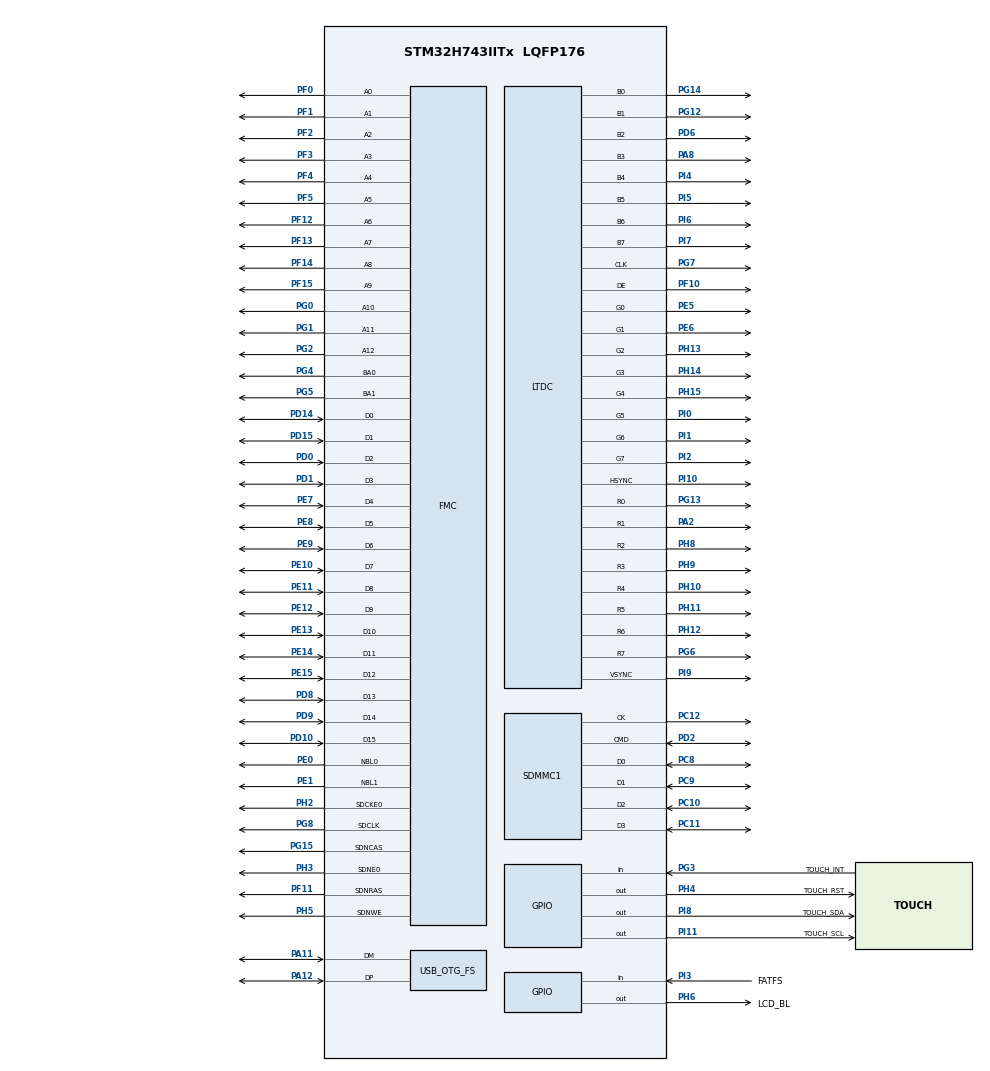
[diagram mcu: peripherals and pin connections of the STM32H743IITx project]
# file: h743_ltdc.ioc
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CORTEX_M7.AccessPermission-Cortex_Memory_Protection_Unit_Region0_Settings=MPU_REGION_FULL_ACCESS
CORTEX_M7.AccessPermission-Cortex_Memory_Protection_Unit_Region1_Settings=MPU_REGION_FULL_ACCESS
CORTEX_M7.AccessPermission-Cortex_Memory_Protection_Unit_Region2_Settings=MPU_REGION_FULL_ACCESS
CORTEX_M7.AccessPermission-Cortex_Memory_Protection_Unit_Region3_Settings=MPU_REGION_FULL_ACCESS
CORTEX_M7.AccessPermission-Cortex_Memory_Protection_Unit_Region4_Settings=MPU_REGION_FULL_ACCESS
CORTEX_M7.BaseAddress-Cortex_Memory_Protection_Unit_Region0_Settings=0x24000000
CORTEX_M7.BaseAddress-Cortex_Memory_Protection_Unit_Region1_Settings=0x30000000
CORTEX_M7.BaseAddress-Cortex_Memory_Protection_Unit_Region2_Settings=0x38000000
CORTEX_M7.BaseAddress-Cortex_Memory_Protection_Unit_Region3_Settings=0xC0000000
CORTEX_M7.BaseAddress-Cortex_Memory_Protection_Unit_Region4_Settings=0x90000000
CORTEX_M7.CPU_DCache=Enabled
CORTEX_M7.CPU_ICache=Enabled
CORTEX_M7.Enable-Cortex_Memory_Protection_Unit_Region0_Settings=MPU_REGION_ENABLE
CORTEX_M7.Enable-Cortex_Memory_Protection_Unit_Region1_Settings=MPU_REGION_ENABLE
CORTEX_M7.Enable-Cortex_Memory_Protection_Unit_Region2_Settings=MPU_REGION_ENABLE
CORTEX_M7.Enable-Cortex_Memory_Protection_Unit_Region3_Settings=MPU_REGION_ENABLE
CORTEX_M7.Enable-Cortex_Memory_Protection_Unit_Region4_Settings=MPU_REGION_ENABLE
CORTEX_M7.IsBufferable-Cortex_Memory_Protection_Unit_Region0_Settings=MPU_ACCESS_BUFFERABLE
CORTEX_M7.IsBufferable-Cortex_Memory_Protection_Unit_Region1_Settings=MPU_ACCESS_BUFFERABLE
CORTEX_M7.IsBufferable-Cortex_Memory_Protection_Unit_Region2_Settings=MPU_ACCESS_BUFFERABLE
CORTEX_M7.IsBufferable-Cortex_Memory_Protection_Unit_Region3_Settings=MPU_ACCESS_BUFFERABLE
CORTEX_M7.IsBufferable-Cortex_Memory_Protection_Unit_Region4_Settings=MPU_ACCESS_BUFFERABLE
CORTEX_M7.IsCacheable-Cortex_Memory_Protection_Unit_Region0_Settings=MPU_ACCESS_CACHEABLE
CORTEX_M7.IsCacheable-Cortex_Memory_Protection_Unit_Region1_Settings=MPU_ACCESS_CACHEABLE
CORTEX_M7.IsCacheable-Cortex_Memory_Protection_Unit_Region2_Settings=MPU_ACCESS_CACHEABLE
CORTEX_M7.IsCacheable-Cortex_Memory_Protection_Unit_Region3_Settings=MPU_ACCESS_CACHEABLE
CORTEX_M7.IsCacheable-Cortex_Memory_Protection_Unit_Region4_Settings=MPU_ACCESS_CACHEABLE
CORTEX_M7.MPU_Control=MPU_PRIVILEGED_DEFAULT
CORTEX_M7.Size-Cortex_Memory_Protection_Unit_Region0_Settings=MPU_REGION_SIZE_512KB
CORTEX_M7.Size-Cortex_Memory_Protection_Unit_Region1_Settings=MPU_REGION_SIZE_512KB
CORTEX_M7.Size-Cortex_Memory_Protection_Unit_Region2_Settings=MPU_REGION_SIZE_64KB
CORTEX_M7.Size-Cortex_Memory_Protection_Unit_Region3_Settings=MPU_REGION_SIZE_32MB
CORTEX_M7.Size-Cortex_Memory_Protection_Unit_Region4_Settings=MPU_REGION_SIZE_8MB
CORTEX_M7.TypeExtField-Cortex_Memory_Protection_Unit_Region0_Settings=MPU_TEX_LEVEL1
CORTEX_M7.TypeExtField-Cortex_Memory_Protection_Unit_Region1_Settings=MPU_TEX_LEVEL1
CORTEX_M7.TypeExtField-Cortex_Memory_Protection_Unit_Region2_Settings=MPU_TEX_LEVEL1
CORTEX_M7.TypeExtField-Cortex_Memory_Protection_Unit_Region3_Settings=MPU_TEX_LEVEL1
CORTEX_M7.TypeExtField-Cortex_Memory_Protection_Unit_Region4_Settings=MPU_TEX_LEVEL1
DMA2D.ColorMode=DMA2D_OUTPUT_RGB888
DMA2D.Mode=DMA2D_R2M
Dma.MEMTOMEM.0.Direction=DMA_MEMORY_TO_MEMORY
Dma.MEMTOMEM.0.EventEnable=DISABLE
Dma.MEMTOMEM.0.FIFOMode=DMA_FIFOMODE_ENABLE
Dma.MEMTOMEM.0.FIFOThreshold=DMA_FIFO_THRESHOLD_FULL
Dma.MEMTOMEM.0.Instance=DMA1_Stream0
Dma.MEMTOMEM.0.MemBurst=DMA_MBURST_SINGLE
Dma.MEMTOMEM.0.MemDataAlignment=DMA_MDATAALIGN_HALFWORD
Dma.MEMTOMEM.0.MemInc=DMA_MINC_ENABLE
Dma.MEMTOMEM.0.Mode=DMA_NORMAL
Dma.MEMTOMEM.0.PeriphBurst=DMA_PBURST_SINGLE
Dma.MEMTOMEM.0.PeriphDataAlignment=DMA_PDATAALIGN_HALFWORD
Dma.MEMTOMEM.0.PeriphInc=DMA_PINC_ENABLE
Dma.MEMTOMEM.0.Polarity=HAL_DMAMUX_REQ_GEN_RISING
Dma.MEMTOMEM.0.Priority=DMA_PRIORITY_LOW
Dma.MEMTOMEM.0.RequestNumber=1
Dma.MEMTOMEM.0.SignalID=NONE
Dma.MEMTOMEM.0.SyncEnable=DISABLE
Dma.MEMTOMEM.0.SyncPolarity=HAL_DMAMUX_SYNC_NO_EVENT
Dma.MEMTOMEM.0.SyncRequestNumber=1
Dma.MEMTOMEM.0.SyncSignalID=NONE
Dma.Request0=MEMTOMEM
FATFS.BSP.number=1
FATFS0.BSP.STBoard=false
FATFS0.BSP.api=Unknown
FATFS0.BSP.i2caddr=0
FATFS0.BSP.instance=PI3
FATFS0.BSP.ip=GPIO
FATFS0.BSP.mode=Input
FATFS0.BSP.name=Detect_SDIO
FATFS0.BSP.solution=PI3
FMC.CASLatency1=FMC_SDRAM_CAS_LATENCY_3
FMC.ColumnBitsNumber1=FMC_SDRAM_COLUMN_BITS_NUM_9
FMC.ExitSelfRefreshDelay1=7
FMC.LoadToActiveDelay1=2
FMC.RCDDelay1=2
FMC.RPDelay1=2
FMC.ReadBurst1=FMC_SDRAM_RBURST_ENABLE
FMC.ReadPipeDelay1=FMC_SDRAM_RPIPE_DELAY_1
FMC.RowCycleDelay1=7
FMC.SDClockPeriod1=FMC_SDRAM_CLOCK_PERIOD_2
FMC.SelfRefreshTime1=4
FMC.WriteRecoveryTime1=3
JPEG.JPEG_RGB_FORMAT=JPEG_RGB888
LTDC.ActiveW=800
LTDC.Alpha0_L0=0
LTDC.Alpha_L0=255
LTDC.BlendingFactor1_L0=LTDC_BLENDING_FACTOR1_CA
LTDC.BlendingFactor2_L0=LTDC_BLENDING_FACTOR2_CA
LTDC.Blue=0
LTDC.DEPolarity=LTDC_DEPOLARITY_AL
LTDC.FBStartAdress_L0=0xC0000000
LTDC.Green=0
LTDC.HBP=88
LTDC.HFP=40
LTDC.HSync=48
LTDC.ImageHeight_L0=480
LTDC.ImageWidth_L0=800
LTDC.Layers=0
LTDC.PixelFormat_L0=LTDC_PIXEL_FORMAT_RGB888
LTDC.Red=0
LTDC.VBP=32
LTDC.VFP=13
LTDC.VSync=3
LTDC.WindowX1_L0=800
LTDC.WindowX1_L1=479
LTDC.WindowY1_L0=480
LTDC.WindowY1_L1=799
Mcu.Family=STM32H7
Mcu.Name=STM32H743IITx
Mcu.Package=LQFP176
NVIC.DMA2D_IRQn=true\:0\:0\:false\:false\:true\:true\:true
NVIC.FMC_IRQn=true\:0\:0\:false\:false\:true\:true\:true
NVIC.JPEG_IRQn=true\:0\:0\:false\:false\:true\:true\:true
NVIC.LTDC_IRQn=true\:0\:0\:false\:false\:true\:true\:true
NVIC.OTG_FS_IRQn=true\:0\:0\:false\:false\:true\:false\:true
NVIC.PriorityGroup=NVIC_PRIORITYGROUP_4
NVIC.SDMMC1_IRQn=true\:0\:0\:false\:false\:true\:true\:true
NVIC.TIM2_IRQn=true\:0\:0\:false\:false\:true\:true\:true
NVIC.TIM3_IRQn=true\:0\:0\:false\:false\:true\:true\:true
NVIC.TIM4_IRQn=true\:0\:0\:false\:false\:true\:true\:true
NVIC.TIM5_IRQn=true\:0\:0\:false\:false\:true\:true\:true
PA11.GPIO_Speed=GPIO_SPEED_FREQ_HIGH
PA11.Mode=Device_Only
PA11.Signal=USB_OTG_FS_DM
PA12.GPIO_Speed=GPIO_SPEED_FREQ_HIGH
PA12.Mode=Device_Only
PA12.Signal=USB_OTG_FS_DP
PA13\ (JTMS/SWDIO).Mode=Serial_Wire
PA13\ (JTMS/SWDIO).Signal=DEBUG_JTMS-SWDIO
PA14\ (JTCK/SWCLK).Mode=Serial_Wire
PA14\ (JTCK/SWCLK).Signal=DEBUG_JTCK-SWCLK
PA2.GPIO_Speed=GPIO_SPEED_FREQ_VERY_HIGH
PA2.Mode=RGB888
PA2.Signal=LTDC_R1
PA8.GPIO_Speed=GPIO_SPEED_FREQ_VERY_HIGH
PA8.Mode=RGB888
PA8.Signal=LTDC_B3
PC10.Mode=SD_4_bits_Wide_bus
PC10.Signal=SDMMC1_D2
PC11.Mode=SD_4_bits_Wide_bus
PC11.Signal=SDMMC1_D3
PC12.Mode=SD_4_bits_Wide_bus
PC12.Signal=SDMMC1_CK
PC14-OSC32_IN\ (OSC32_IN).Mode=LSE-External-Oscillator
PC14-OSC32_IN\ (OSC32_IN).Signal=RCC_OSC32_IN
PC15-OSC32_OUT\ (OSC32_OUT).Mode=LSE-External-Oscillator
PC15-OSC32_OUT\ (OSC32_OUT).Signal=RCC_OSC32_OUT
PC8.Mode=SD_4_bits_Wide_bus
PC8.Signal=SDMMC1_D0
PC9.Mode=SD_4_bits_Wide_bus
PC9.Signal=SDMMC1_D1
PD0.Signal=FMC_D2_DA2
PD1.Signal=FMC_D3_DA3
PD10.Signal=FMC_D15_DA15
PD14.Signal=FMC_D0_DA0
PD15.Signal=FMC_D1_DA1
PD2.Mode=SD_4_bits_Wide_bus
PD2.Signal=SDMMC1_CMD
PD6.GPIO_Speed=GPIO_SPEED_FREQ_VERY_HIGH
PD6.Mode=RGB888
PD6.Signal=LTDC_B2
PD8.Signal=FMC_D13_DA13
PD9.Signal=FMC_D14_DA14
PE0.Signal=FMC_NBL0
PE1.Signal=FMC_NBL1
PE10.Signal=FMC_D7_DA7
PE11.Signal=FMC_D8_DA8
PE12.Signal=FMC_D9_DA9
PE13.Signal=FMC_D10_DA10
PE14.Signal=FMC_D11_DA11
PE15.Signal=FMC_D12_DA12
PE5.GPIO_Speed=GPIO_SPEED_FREQ_VERY_HIGH
PE5.Mode=RGB888
PE5.Signal=LTDC_G0
PE6.GPIO_Speed=GPIO_SPEED_FREQ_VERY_HIGH
PE6.Mode=RGB888
PE6.Signal=LTDC_G1
PE7.Signal=FMC_D4_DA4
PE8.Signal=FMC_D5_DA5
PE9.Signal=FMC_D6_DA6
PF0.Signal=FMC_A0
PF1.Signal=FMC_A1
PF10.GPIO_Speed=GPIO_SPEED_FREQ_VERY_HIGH
PF10.Mode=RGB888
PF10.Signal=LTDC_DE
PF11.Signal=FMC_SDNRAS
PF12.Signal=FMC_A6
PF13.Signal=FMC_A7
PF14.Signal=FMC_A8
PF15.Signal=FMC_A9
PF2.Signal=FMC_A2
PF3.Signal=FMC_A3
PF4.Signal=FMC_A4
PF5.Signal=FMC_A5
PG0.Signal=FMC_A10
PG1.Signal=FMC_A11
PG12.GPIO_Speed=GPIO_SPEED_FREQ_VERY_HIGH
PG12.Mode=RGB888
PG12.Signal=LTDC_B1
PG13.GPIO_Speed=GPIO_SPEED_FREQ_VERY_HIGH
PG13.Mode=RGB888
PG13.Signal=LTDC_R0
PG14.GPIO_Speed=GPIO_SPEED_FREQ_VERY_HIGH
PG14.Mode=RGB888
PG14.Signal=LTDC_B0
PG15.Signal=FMC_SDNCAS
PG2.Signal=FMC_A12
PG3.GPIO_Label=TOUCH_INT
PG3.Signal=GPIO_Input
PG4.Signal=FMC_A14_BA0
PG5.Signal=FMC_A15_BA1
PG6.GPIO_Speed=GPIO_SPEED_FREQ_VERY_HIGH
PG6.Mode=RGB888
PG6.Signal=LTDC_R7
PG7.GPIO_Speed=GPIO_SPEED_FREQ_VERY_HIGH
PG7.Mode=RGB888
PG7.Signal=LTDC_CLK
PG8.Signal=FMC_SDCLK
PH0-OSC_IN\ (PH0).Mode=HSE-External-Oscillator
PH0-OSC_IN\ (PH0).Signal=RCC_OSC_IN
PH1-OSC_OUT\ (PH1).Mode=HSE-External-Oscillator
PH1-OSC_OUT\ (PH1).Signal=RCC_OSC_OUT
PH10.GPIO_Speed=GPIO_SPEED_FREQ_VERY_HIGH
PH10.Mode=RGB888
PH10.Signal=LTDC_R4
PH11.GPIO_Speed=GPIO_SPEED_FREQ_VERY_HIGH
PH11.Mode=RGB888
PH11.Signal=LTDC_R5
PH12.GPIO_Speed=GPIO_SPEED_FREQ_VERY_HIGH
PH12.Mode=RGB888
PH12.Signal=LTDC_R6
PH13.GPIO_Speed=GPIO_SPEED_FREQ_VERY_HIGH
PH13.Mode=RGB888
PH13.Signal=LTDC_G2
PH14.GPIO_Speed=GPIO_SPEED_FREQ_VERY_HIGH
PH14.Mode=RGB888
PH14.Signal=LTDC_G3
PH15.GPIO_Speed=GPIO_SPEED_FREQ_VERY_HIGH
PH15.Mode=RGB888
PH15.Signal=LTDC_G4
PH2.Mode=SdramChipSelect1_1
PH2.Signal=FMC_SDCKE0
PH3.Mode=SdramChipSelect1_1
PH3.Signal=FMC_SDNE0
PH4.GPIO_Label=TOUCH_RST
PH4.GPIO_PuPd=GPIO_PULLUP
PH4.Signal=GPIO_Output
PH5.Signal=FMC_SDNWE
PH6.GPIO_Label=LCD_BL
PH6.GPIO_PuPd=GPIO_PULLUP
PH6.Signal=GPIO_Output
PH8.GPIO_Speed=GPIO_SPEED_FREQ_VERY_HIGH
PH8.Mode=RGB888
PH8.Signal=LTDC_R2
PH9.GPIO_Speed=GPIO_SPEED_FREQ_VERY_HIGH
PH9.Mode=RGB888
PH9.Signal=LTDC_R3
PI0.GPIO_Speed=GPIO_SPEED_FREQ_VERY_HIGH
PI0.Mode=RGB888
PI0.Signal=LTDC_G5
PI1.GPIO_Speed=GPIO_SPEED_FREQ_VERY_HIGH
PI1.Mode=RGB888
PI1.Signal=LTDC_G6
PI10.GPIO_Speed=GPIO_SPEED_FREQ_VERY_HIGH
PI10.Mode=RGB888
PI10.Signal=LTDC_HSYNC
PI11.GPIO_Label=TOUCH_SCL
PI11.GPIO_PuPd=GPIO_PULLUP
PI11.Signal=GPIO_Output
PI2.GPIO_Speed=GPIO_SPEED_FREQ_VERY_HIGH
PI2.Mode=RGB888
PI2.Signal=LTDC_G7
PI3.GPIO_Label=FATFS
PI3.GPIO_PuPd=GPIO_PULLDOWN
PI3.Signal=GPIO_Input
PI4.GPIO_Speed=GPIO_SPEED_FREQ_VERY_HIGH
PI4.Mode=RGB888
PI4.Signal=LTDC_B4
PI5.GPIO_Speed=GPIO_SPEED_FREQ_VERY_HIGH
PI5.Mode=RGB888
PI5.Signal=LTDC_B5
PI6.GPIO_Speed=GPIO_SPEED_FREQ_VERY_HIGH
PI6.Mode=RGB888
PI6.Signal=LTDC_B6
PI7.GPIO_Speed=GPIO_SPEED_FREQ_VERY_HIGH
PI7.Mode=RGB888
PI7.Signal=LTDC_B7
PI8.GPIO_Label=TOUCH_SDA
PI8.GPIO_PuPd=GPIO_PULLUP
PI8.Signal=GPIO_Output
PI9.GPIO_Speed=GPIO_SPEED_FREQ_VERY_HIGH
PI9.Mode=RGB888
PI9.Signal=LTDC_VSYNC
ProjectManager.HeapSize=0x2000
ProjectManager.StackSize=0x2000
ProjectManager.TargetToolchain=STM32CubeIDE
RCC.ADCFreq_Value=50390625
RCC.APB1Freq_Value=120000000
RCC.APB2Freq_Value=120000000
RCC.APB3Freq_Value=120000000
RCC.APB4Freq_Value=120000000
RCC.CortexFreq_Value=480000000
RCC.D1PPRE=RCC_APB3_DIV2
RCC.D2PPRE1=RCC_APB1_DIV2
RCC.D2PPRE2=RCC_APB2_DIV2
RCC.D3PPRE=RCC_APB4_DIV2
RCC.DIVM1=5
RCC.DIVM3=25
RCC.DIVN1=192
RCC.DIVN3=192
RCC.DIVQ1=32
RCC.DIVQ3=4
RCC.DIVR3=6
RCC.HCLKFreq_Value=240000000
RCC.HPRE=RCC_HCLK_DIV2
RCC.PLLSourceVirtual=RCC_PLLSOURCE_HSE
RCC.SYSCLKFreq_VALUE=480000000
RCC.SYSCLKSource=RCC_SYSCLKSOURCE_PLLCLK
RCC.USBCLockSelection=RCC_USBCLKSOURCE_PLL3
RCC.USBFreq_Value=48000000
SH.FMC_A0.0=FMC_A0,13b-sda1
SH.FMC_A1.0=FMC_A1,13b-sda1
SH.FMC_A10.0=FMC_A10,13b-sda1
SH.FMC_A11.0=FMC_A11,13b-sda1
SH.FMC_A12.0=FMC_A12,13b-sda1
SH.FMC_A14_BA0.0=FMC_BA0,FourSdramBanks1
SH.FMC_A15_BA1.0=FMC_BA1,FourSdramBanks1
SH.FMC_A2.0=FMC_A2,13b-sda1
SH.FMC_A3.0=FMC_A3,13b-sda1
SH.FMC_A4.0=FMC_A4,13b-sda1
SH.FMC_A5.0=FMC_A5,13b-sda1
SH.FMC_A6.0=FMC_A6,13b-sda1
SH.FMC_A7.0=FMC_A7,13b-sda1
SH.FMC_A8.0=FMC_A8,13b-sda1
SH.FMC_A9.0=FMC_A9,13b-sda1
SH.FMC_D0_DA0.0=FMC_D0,sd-16b-d1
SH.FMC_D10_DA10.0=FMC_D10,sd-16b-d1
SH.FMC_D11_DA11.0=FMC_D11,sd-16b-d1
SH.FMC_D12_DA12.0=FMC_D12,sd-16b-d1
SH.FMC_D13_DA13.0=FMC_D13,sd-16b-d1
SH.FMC_D14_DA14.0=FMC_D14,sd-16b-d1
SH.FMC_D15_DA15.0=FMC_D15,sd-16b-d1
SH.FMC_D1_DA1.0=FMC_D1,sd-16b-d1
SH.FMC_D2_DA2.0=FMC_D2,sd-16b-d1
SH.FMC_D3_DA3.0=FMC_D3,sd-16b-d1
SH.FMC_D4_DA4.0=FMC_D4,sd-16b-d1
SH.FMC_D5_DA5.0=FMC_D5,sd-16b-d1
SH.FMC_D6_DA6.0=FMC_D6,sd-16b-d1
SH.FMC_D7_DA7.0=FMC_D7,sd-16b-d1
SH.FMC_D8_DA8.0=FMC_D8,sd-16b-d1
SH.FMC_D9_DA9.0=FMC_D9,sd-16b-d1
SH.FMC_NBL0.0=FMC_NBL0,Sd2ByteEnable1
SH.FMC_NBL1.0=FMC_NBL1,Sd2ByteEnable1
SH.FMC_SDCLK.0=FMC_SDCLK,13b-sda1
SH.FMC_SDNCAS.0=FMC_SDNCAS,13b-sda1
SH.FMC_SDNRAS.0=FMC_SDNRAS,13b-sda1
SH.FMC_SDNWE.0=FMC_SDNWE,13b-sda1
USB_DEVICE.CLASS_NAME_FS=CDC
USB_DEVICE.VirtualMode-CDC_FS=Cdc
USB_DEVICE.VirtualModeFS=Cdc_FS
USB_OTG_FS.VirtualMode=Device_Only
VP_DMA2D_VS_DMA2D.Mode=DMA2D_Activate
VP_FATFS_VS_SDIO.Mode=SDIO
VP_JPEG_VS_JPEG.Mode=JPEG_Activate
VP_TIM2_VS_ClockSourceINT.Mode=Internal
VP_TIM3_VS_ClockSourceINT.Mode=Internal
VP_TIM4_VS_ClockSourceINT.Mode=Internal
VP_TIM5_VS_ClockSourceINT.Mode=Internal
VP_USB_DEVICE_VS_USB_DEVICE_CDC_FS.Mode=CDC_FS
board=custom

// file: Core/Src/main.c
/* USER CODE BEGIN Header */
/**
  ******************************************************************************
  * @file           : main.c
  * @brief          : Main program body
  ******************************************************************************
  * @attention
  *
  * Copyright (c) 2023 STMicroelectronics.
  * All rights reserved.
  *
  * This software is licensed under terms that can be found in the LICENSE file
  * in the root directory of this software component.
  * If no LICENSE file comes with this software, it is provided AS-IS.
  *
  ******************************************************************************
  */
/* USER CODE END Header */
#include "main.h"
#include "dma.h"
#include "dma2d.h"
#include "fatfs.h"
#include "jpeg.h"
#include "ltdc.h"
#include "sdmmc.h"
#include "tim.h"
#include "usb_device.h"
#include "gpio.h"
#include "fmc.h"

/* USER CODE BEGIN Includes */
#include <stdio.h>
#include <string.h>
#include <stdlib.h>
#include "usbd_cdc_if.h"
#include "pic.h"

extern unsigned char gImage_pic[];
/* USER CODE END Includes */

/* USER CODE BEGIN PD */
#define one_clk_time	0.00416666f
#define SDRAM_Size 		32*1024*1024
#define SDRAM_BASEADDRESS	0xC0000000
#define DTCM_BASEADDRESS	0x20000000

#define LCD_ON	HAL_GPIO_WritePin(GPIOH, GPIO_PIN_6, GPIO_PIN_SET)
#define LCD_OFF	HAL_GPIO_WritePin(GPIOH, GPIO_PIN_6, GPIO_PIN_RESET)

/* USER CODE END PD */

void SystemClock_Config(void);
void PeriphCommonClock_Config(void);
static void MPU_Config(void);

/* USER CODE BEGIN 0 */
#define	p_buf

#ifdef	p_buf
	uint16_t *buf = (uint16_t *)0xC0000000;
#else
	SDRAM uint16_t buf[SDRAM_Size/2] = {0};
#endif
uint32_t	tim_start,tim_end;
uint32_t	tim_long;
float		time_us;
uint32_t Get_TIM_CNT(TIM_HandleTypeDef htim)
{
	return	htim.Instance->CNT;
}

uint8_t SDRAM_Test(void)
{
	volatile uint32_t  i = 0;			// ¼ÆÊý±äÁ¿
	uint32_t k = 0;
	uint16_t ReadData = 0; 	// ¶ÁÈ¡µ½µÄÊý¾Ý
	uint32_t Err_Num = 0;

	float    ExecutionSpeed;			// Ö´ÐÐËÙ¶È
	htim2.Instance->CNT = 0;
	tim_start = Get_TIM_CNT(htim2);
	HAL_TIM_Base_Start(&htim2);
	HAL_Delay(100);
	tim_end = Get_TIM_CNT(htim2);
	HAL_TIM_Base_Stop(&htim2);
	tim_long = tim_end - tim_start;
	time_us = tim_long * one_clk_time;
	usb_printf("\r\n delay %.2f us!\r\n", time_us);
	HAL_Delay(10);

	usb_printf("\r\n SDRAM Write an Read test start!\r\n");
	HAL_Delay(10);

	htim2.Instance->CNT = 0;
	tim_start = Get_TIM_CNT(htim2);
	HAL_TIM_Base_Start(&htim2);
	for (k = 0; k < SDRAM_Size/2; k++)
	{
		buf[k] = (uint16_t)k;
	}
	tim_end = Get_TIM_CNT(htim2);
	HAL_TIM_Base_Stop(&htim2);
	tim_long = tim_end - tim_start;
	time_us = tim_long * one_clk_time;
	ExecutionSpeed = (float)SDRAM_Size /1024/1024 /time_us*1000*1000 ;

	usb_printf("\r\nWrite Speed is %.2f MB/s\r\n",ExecutionSpeed);
	HAL_Delay(10);

	htim2.Instance->CNT = 0;
	tim_start = Get_TIM_CNT(htim2);
	HAL_TIM_Base_Start(&htim2);
	for(i = 0; i < SDRAM_Size/2;i++ )
	{
		ReadData = buf[i];  // ´ÓSDRAM¶Á³öÊý¾Ý
	}
	tim_end = Get_TIM_CNT(htim2);
	HAL_TIM_Base_Stop(&htim2);
	tim_long = tim_end - tim_start;
	time_us = tim_long * one_clk_time;

	ExecutionSpeed = (float)SDRAM_Size /1024/1024 /time_us*1000*1000 ;

	usb_printf("\r\nRead Speed is %.2f MB/s\r\n",ExecutionSpeed);
	HAL_Delay(10);

	usb_printf("\r\nstart 16bits test\r\n");
	HAL_Delay(10);
	for(i = 0; i < SDRAM_Size/2;i++ )
	{
		ReadData = buf[i];
		if( ReadData != (uint16_t)i )
		{
			Err_Num++;
		}
	}
	if(Err_Num != 0){
		usb_printf("\r\nSDRAM test failed , %d\r\n", Err_Num);
		HAL_Delay(10);
		return ERROR;
	}

	usb_printf("SDRAM OK\r\n");
	return SUCCESS;
}

uint8_t *frame_buf = (uint8_t *)(SDRAM_BASEADDRESS);
uint8_t *frame = (uint8_t *)(SDRAM_BASEADDRESS + 800*480*3);

void DMA2D_FillColor(uint16_t sx, uint16_t sy, uint16_t ex, uint16_t ey, uint32_t color)
{

	uint32_t addr = (uint32_t)frame_buf + 3*(800*sy + sx);
	uint32_t offline = 800 - (ex - sx + 1);

	__HAL_RCC_DMA2D_CLK_ENABLE();
	DMA2D->CR &= ~DMA2D_CR_START;
	DMA2D->CR = DMA2D_R2M;
	DMA2D->OPFCCR = LTDC_PIXEL_FORMAT_RGB888;
	DMA2D->OMAR = addr;

	DMA2D->OOR = offline;
	DMA2D->NLR = ((ex - sx + 1) << 16) | ((ey - sy + 1) << 0);
	DMA2D->OCOLR = color;

	DMA2D->CR |= DMA2D_CR_START;

	while((DMA2D->ISR & DMA2D_FLAG_TC) == 0)
	{

	}
	DMA2D->IFCR |= DMA2D_FLAG_TC;
}

void DMA2D_FillFrame(uint16_t sx, uint16_t sy, uint16_t ex, uint16_t ey, uint32_t *color)
{

	uint32_t addr = (uint32_t)frame_buf + 3*(800*sy + sx);
	uint32_t offline = 800 - (ex - sx + 1);
	uint32_t size = (ex - sx + 1)*(ey - sy + 1)*3;

	__HAL_RCC_DMA2D_CLK_ENABLE();
	DMA2D->CR &= ~DMA2D_CR_START;
	DMA2D->CR = DMA2D_M2M;
	DMA2D->FGPFCCR = LTDC_PIXEL_FORMAT_RGB888;

	DMA2D->FGMAR = (uint32_t)color;
	DMA2D->OMAR = addr;

	DMA2D->FGOR = 0;
	DMA2D->OOR = offline;
	DMA2D->NLR = ((ex - sx + 1) << 16) | ((ey - sy + 1) << 0);

	SCB_CleanDCache_by_Addr((uint32_t *)color, size);
//	SCB_CleanDCache();

	DMA2D->CR |= DMA2D_CR_START;

	while((DMA2D->ISR & DMA2D_FLAG_TC) == 0)
	{

	}
	DMA2D->IFCR |= DMA2D_FLAG_TC;
}

uint32_t color = 0xff;
uint32_t cnt = 0;

/* USER CODE END 0 */

int main(void)
{

  /* MPU Configuration--------------------------------------------------------*/
  MPU_Config();

  /* Enable I-Cache---------------------------------------------------------*/
  SCB_EnableICache();

  /* Enable D-Cache---------------------------------------------------------*/
  SCB_EnableDCache();//刷屏后记得FlushDCache，不然会有画面问题

  /* MCU Configuration--------------------------------------------------------*/

  /* Reset of all peripherals, Initializes the Flash interface and the Systick. */
  HAL_Init();

  /* Configure the system clock */
  SystemClock_Config();

/* Configure the peripherals common clocks */
  PeriphCommonClock_Config();

  /* Initialize all configured peripherals */
  MX_GPIO_Init();
  MX_DMA2D_Init();
  MX_FMC_Init();
  MX_JPEG_Init();
  MX_LTDC_Init();
  MX_SDMMC1_SD_Init();
  MX_TIM2_Init();
  MX_TIM3_Init();
  MX_TIM4_Init();
  MX_TIM5_Init();
  MX_FATFS_Init();
  MX_DMA_Init();
  MX_USB_DEVICE_Init();
  /* USER CODE BEGIN 2 */
  LCD_ON;

//  for(int i=0; i<480*800*3; i++)
//  {
//	  if(i%3==0)
//		  frame_buf[i] = 0xff;
//	  else if(i%3==1)
//		  frame_buf[i] = 0xff;
//	  else if(i%3==2)
//		  frame_buf[i] = 0xff;
//  }
  DMA2D_FillColor(0, 0, 799, 479, 0x00);

  uint32_t *p = (uint32_t *)0x20000000;
  *p = 0xffffffff;
  /* USER CODE END 2 */

  /* Infinite loop */
  while (1)
  {

    /* USER CODE BEGIN 3 */

	  //SDRAM_Test();
//	  for(int i=0; i<480*800*3; i++)
//	  {
//		  if(i%3==0)
//			  frame[i] = color;
//		  else if(i%3==1)
//			  frame[i] = color>>8;
//		  else if(i%3==2)
//			  frame[i] = color>>16;
//	  }
	  //SCB_CleanDCache_by_Addr((uint32_t *)frame, 3*800*480);
//	  color++;
//	  DMA2D_FillFrame(0, 0, 799, 479, (uint32_t *)frame);
//	  DMA2D_FillFrame(0, 0, 773, 479, (uint32_t *)gImage_pic);

	  DMA2D_FillColor(0, 0, 199, 479, 0xff);
	  DMA2D_FillColor(199, 0, 399, 479, 0xff00);
	  DMA2D_FillColor(399, 0, 599, 479, 0xff0000);
	  DMA2D_FillColor(599, 0, 799, 479, 0xffffff);

	  if(color == 0xff0000)
		  color = 0xff;
	  else
		  color = color << 8;
	  usb_printf("%d", cnt++);
	  //HAL_LTDC_Reload(&hltdc, LTDC_RELOAD_IMMEDIATE);
	  //HAL_Delay(1000);

  }
  /* USER CODE END 3 */
}

void SystemClock_Config(void)
{
  RCC_OscInitTypeDef RCC_OscInitStruct = {0};
  RCC_ClkInitTypeDef RCC_ClkInitStruct = {0};

  /** Supply configuration update enable
  */
  HAL_PWREx_ConfigSupply(PWR_LDO_SUPPLY);
  /** Configure the main internal regulator output voltage
  */
  __HAL_PWR_VOLTAGESCALING_CONFIG(PWR_REGULATOR_VOLTAGE_SCALE0);

  while(!__HAL_PWR_GET_FLAG(PWR_FLAG_VOSRDY)) {}
  /** Macro to configure the PLL clock source
  */
  __HAL_RCC_PLL_PLLSOURCE_CONFIG(RCC_PLLSOURCE_HSE);
  /** Initializes the RCC Oscillators according to the specified parameters
  * in the RCC_OscInitTypeDef structure.
  */
  RCC_OscInitStruct.OscillatorType = RCC_OSCILLATORTYPE_HSE;
  RCC_OscInitStruct.HSEState = RCC_HSE_ON;
  RCC_OscInitStruct.PLL.PLLState = RCC_PLL_ON;
  RCC_OscInitStruct.PLL.PLLSource = RCC_PLLSOURCE_HSE;
  RCC_OscInitStruct.PLL.PLLM = 5;
  RCC_OscInitStruct.PLL.PLLN = 192;
  RCC_OscInitStruct.PLL.PLLP = 2;
  RCC_OscInitStruct.PLL.PLLQ = 32;
  RCC_OscInitStruct.PLL.PLLR = 2;
  RCC_OscInitStruct.PLL.PLLRGE = RCC_PLL1VCIRANGE_2;
  RCC_OscInitStruct.PLL.PLLVCOSEL = RCC_PLL1VCOWIDE;
  RCC_OscInitStruct.PLL.PLLFRACN = 0;
  if (HAL_RCC_OscConfig(&RCC_OscInitStruct) != HAL_OK)
  {
    Error_Handler();
  }
  /** Initializes the CPU, AHB and APB buses clocks
  */
  RCC_ClkInitStruct.ClockType = RCC_CLOCKTYPE_HCLK|RCC_CLOCKTYPE_SYSCLK
                              |RCC_CLOCKTYPE_PCLK1|RCC_CLOCKTYPE_PCLK2
                              |RCC_CLOCKTYPE_D3PCLK1|RCC_CLOCKTYPE_D1PCLK1;
  RCC_ClkInitStruct.SYSCLKSource = RCC_SYSCLKSOURCE_PLLCLK;
  RCC_ClkInitStruct.SYSCLKDivider = RCC_SYSCLK_DIV1;
  RCC_ClkInitStruct.AHBCLKDivider = RCC_HCLK_DIV2;
  RCC_ClkInitStruct.APB3CLKDivider = RCC_APB3_DIV2;
  RCC_ClkInitStruct.APB1CLKDivider = RCC_APB1_DIV2;
  RCC_ClkInitStruct.APB2CLKDivider = RCC_APB2_DIV2;
  RCC_ClkInitStruct.APB4CLKDivider = RCC_APB4_DIV2;

  if (HAL_RCC_ClockConfig(&RCC_ClkInitStruct, FLASH_LATENCY_4) != HAL_OK)
  {
    Error_Handler();
  }
}

void PeriphCommonClock_Config(void)
{
  RCC_PeriphCLKInitTypeDef PeriphClkInitStruct = {0};

  /** Initializes the peripherals clock
  */
  PeriphClkInitStruct.PeriphClockSelection = RCC_PERIPHCLK_USB|RCC_PERIPHCLK_LTDC;
  PeriphClkInitStruct.PLL3.PLL3M = 25;
  PeriphClkInitStruct.PLL3.PLL3N = 192;
  PeriphClkInitStruct.PLL3.PLL3P = 2;
  PeriphClkInitStruct.PLL3.PLL3Q = 4;
  PeriphClkInitStruct.PLL3.PLL3R = 6;
  PeriphClkInitStruct.PLL3.PLL3RGE = RCC_PLL3VCIRANGE_0;
  PeriphClkInitStruct.PLL3.PLL3VCOSEL = RCC_PLL3VCOWIDE;
  PeriphClkInitStruct.PLL3.PLL3FRACN = 0;
  PeriphClkInitStruct.UsbClockSelection = RCC_USBCLKSOURCE_PLL3;
  if (HAL_RCCEx_PeriphCLKConfig(&PeriphClkInitStruct) != HAL_OK)
  {
    Error_Handler();
  }
}

/* MPU Configuration */

void MPU_Config(void)
{
  MPU_Region_InitTypeDef MPU_InitStruct = {0};

  /* Disables the MPU */
  HAL_MPU_Disable();
  /** Initializes and configures the Region and the memory to be protected
  */
  MPU_InitStruct.Enable = MPU_REGION_ENABLE;
  MPU_InitStruct.Number = MPU_REGION_NUMBER0;
  MPU_InitStruct.BaseAddress = 0x24000000;
  MPU_InitStruct.Size = MPU_REGION_SIZE_512KB;
  MPU_InitStruct.SubRegionDisable = 0x0;
  MPU_InitStruct.TypeExtField = MPU_TEX_LEVEL1;
  MPU_InitStruct.AccessPermission = MPU_REGION_FULL_ACCESS;
  MPU_InitStruct.DisableExec = MPU_INSTRUCTION_ACCESS_ENABLE;
  MPU_InitStruct.IsShareable = MPU_ACCESS_NOT_SHAREABLE;
  MPU_InitStruct.IsCacheable = MPU_ACCESS_CACHEABLE;
  MPU_InitStruct.IsBufferable = MPU_ACCESS_BUFFERABLE;

  HAL_MPU_ConfigRegion(&MPU_InitStruct);
  /** Initializes and configures the Region and the memory to be protected
  */
  MPU_InitStruct.Number = MPU_REGION_NUMBER1;
  MPU_InitStruct.BaseAddress = 0x30000000;

  HAL_MPU_ConfigRegion(&MPU_InitStruct);
  /** Initializes and configures the Region and the memory to be protected
  */
  MPU_InitStruct.Number = MPU_REGION_NUMBER2;
  MPU_InitStruct.BaseAddress = 0x38000000;
  MPU_InitStruct.Size = MPU_REGION_SIZE_64KB;

  HAL_MPU_ConfigRegion(&MPU_InitStruct);
  /** Initializes and configures the Region and the memory to be protected
  */
  MPU_InitStruct.Number = MPU_REGION_NUMBER3;
  MPU_InitStruct.BaseAddress = 0xC0000000;
  MPU_InitStruct.Size = MPU_REGION_SIZE_32MB;

  HAL_MPU_ConfigRegion(&MPU_InitStruct);
  /** Initializes and configures the Region and the memory to be protected
  */
  MPU_InitStruct.Number = MPU_REGION_NUMBER4;
  MPU_InitStruct.BaseAddress = 0x90000000;
  MPU_InitStruct.Size = MPU_REGION_SIZE_8MB;

  HAL_MPU_ConfigRegion(&MPU_InitStruct);
  /* Enables the MPU */
  HAL_MPU_Enable(MPU_PRIVILEGED_DEFAULT);

}

void Error_Handler(void)
{
  __disable_irq();
  while (1)
  {
  }
}
